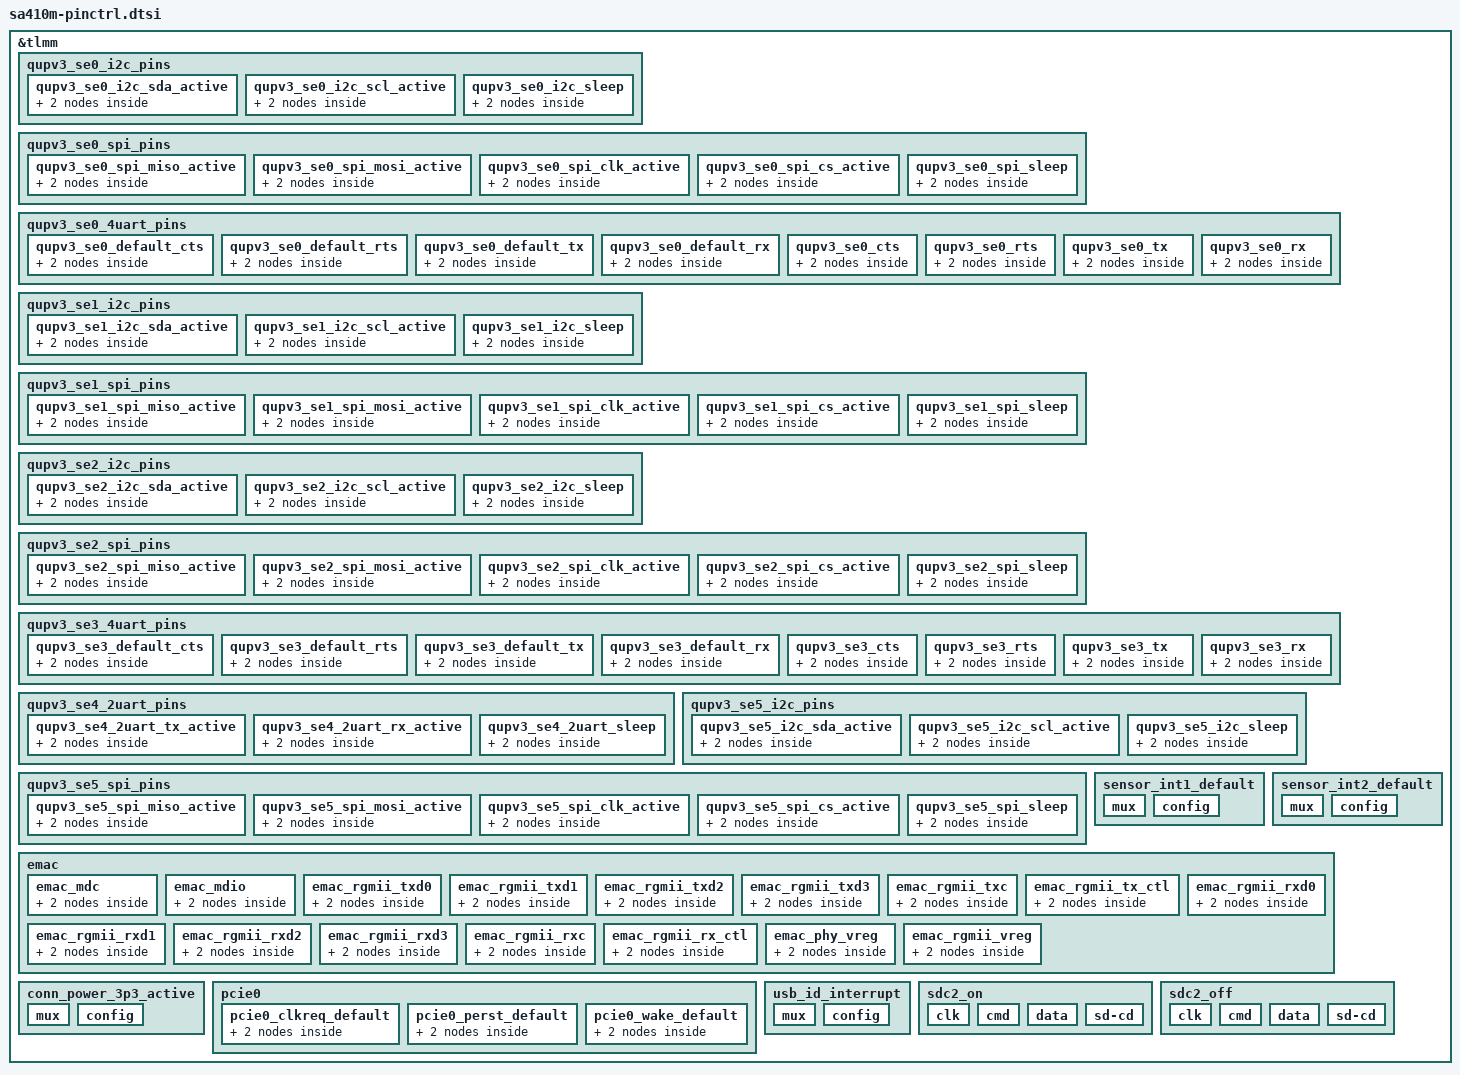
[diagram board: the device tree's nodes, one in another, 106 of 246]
&tlmm {
	qupv3_se0_i2c_pins: qupv3_se0_i2c_pins {
		qupv3_se0_i2c_sda_active: qupv3_se0_i2c_sda_active {
			mux {
				pins = "gpio0";
				function = "qup0_se0_l0";
			};

			config {
				pins = "gpio0";
				drive-strength = <2>;
				bias-pull-up;
			};
		};

		qupv3_se0_i2c_scl_active: qupv3_se0_i2c_scl_active {
			mux {
				pins = "gpio1";
				function = "qup0_se0_l1";
			};

			config {
				pins = "gpio1";
				drive-strength = <2>;
				bias-pull-up;
			};
		};

		qupv3_se0_i2c_sleep: qupv3_se0_i2c_sleep {
			mux {
				pins = "gpio0", "gpio1";
				function = "gpio";
			};

			config {
				pins = "gpio0", "gpio1";
				drive-strength = <2>;
				bias-disable;
			};
		};
	};

	qupv3_se0_spi_pins: qupv3_se0_spi_pins {
		qupv3_se0_spi_miso_active: qupv3_se0_spi_miso_active {
			mux {
				pins = "gpio0";
				function = "qup0_se0_l0";
			};

			config {
				pins = "gpio0";
				drive-strength = <6>;
				bias-disable;
			};
		};

		qupv3_se0_spi_mosi_active: qupv3_se0_spi_mosi_active {
			mux {
				pins = "gpio1";
				function = "qup0_se0_l1";
			};

			config {
				pins = "gpio1";
				drive-strength = <6>;
				bias-disable;
			};
		};

		qupv3_se0_spi_clk_active: qupv3_se0_spi_clk_active {
			mux {
				pins = "gpio2";
				function = "qup0_se0_l2";
			};

			config {
				pins = "gpio2";
				drive-strength = <6>;
				bias-disable;
			};
		};

		qupv3_se0_spi_cs_active: qupv3_se0_spi_cs_active {
			mux {
				pins = "gpio3";
				function = "qup0_se0_l3";
			};

			config {
				pins = "gpio3";
				drive-strength = <6>;
				bias-disable;
			};
		};

		qupv3_se0_spi_sleep: qupv3_se0_spi_sleep {
			mux {
				pins = "gpio0", "gpio1",
					"gpio2", "gpio3";
				function = "gpio";
			};

			config {
				pins = "gpio0", "gpio1",
					"gpio2", "gpio3";
				drive-strength = <2>;
				bias-disable;
			};
		};
	};

	qupv3_se0_4uart_pins: qupv3_se0_4uart_pins {
		qupv3_se0_default_cts: qupv3_se0_default_cts {
			mux {
				pins = "gpio0";
				function = "gpio";
			};

			config {
				pins = "gpio0";
				drive-strength = <2>;
				bias-disable;
			};
		};

		qupv3_se0_default_rts: qupv3_se0_default_rts {
			mux {
				pins = "gpio1";
				function = "gpio";
			};

			config {
				pins = "gpio1";
				drive-strength = <2>;
				bias-pull-down;
			};
		};

		qupv3_se0_default_tx: qupv3_se0_default_tx {
			mux {
				pins = "gpio2";
				function = "gpio";
			};

			config {
				pins = "gpio2";
				drive-strength = <2>;
				bias-pull-up;
			};
		};

		qupv3_se0_default_rx: qupv3_se0_default_rx {
			mux {
				pins = "gpio3";
				function = "gpio";
			};

			config {
				pins = "gpio3";
				drive-strength = <2>;
				bias-pull-down;
			};
		};

		qupv3_se0_cts: qupv3_se0_cts {
			mux {
				pins = "gpio0";
				function = "qup0_se0_l0";
			};

			config {
				pins = "gpio0";
				drive-strength = <2>;
				bias-disable;
			};
		};

		qupv3_se0_rts: qupv3_se0_rts {
			mux {
				pins = "gpio1";
				function = "qup0_se0_l1";
			};

			config {
				pins = "gpio1";
				drive-strength = <2>;
				bias-pull-down;
			};
		};

		qupv3_se0_tx: qupv3_se0_tx {
			mux {
				pins = "gpio2";
				function = "qup0_se0_l2";
			};

			config {
				pins = "gpio2";
				drive-strength = <2>;
				bias-pull-up;
			};
		};

		qupv3_se0_rx: qupv3_se0_rx {
			mux {
				pins = "gpio3";
				function = "qup0_se0_l3";
			};

			config {
				pins = "gpio3";
				drive-strength = <2>;
				bias-disable;
			};
		};
	};

	qupv3_se1_i2c_pins: qupv3_se1_i2c_pins {
		qupv3_se1_i2c_sda_active: qupv3_se1_i2c_sda_active {
			mux {
				pins = "gpio4";
				function = "qup0_se1_l0";
			};

			config {
				pins = "gpio4";
				drive-strength = <2>;
				bias-pull-up;
			};
		};

		qupv3_se1_i2c_scl_active: qupv3_se1_i2c_scl_active {
			mux {
				pins = "gpio5";
				function = "qup0_se1_l1";
			};

			config {
				pins = "gpio5";
				drive-strength = <2>;
				bias-pull-up;
			};
		};

		qupv3_se1_i2c_sleep: qupv3_se1_i2c_sleep {
			mux {
				pins = "gpio4", "gpio5";
				function = "gpio";
			};

			config {
				pins = "gpio4", "gpio5";
				drive-strength = <2>;
				bias-disable;
			};
		};
	};

	qupv3_se1_spi_pins: qupv3_se1_spi_pins {
		qupv3_se1_spi_miso_active: qupv3_se1_spi_miso_active {
			mux {
				pins = "gpio4";
				function = "qup0_se1_l0";
			};

			config {
				pins = "gpio4";
				drive-strength = <6>;
				bias-disable;
			};
		};

		qupv3_se1_spi_mosi_active: qupv3_se1_spi_mosi_active {
			mux {
				pins = "gpio5";
				function = "qup0_se1_l1";
			};

			config {
				pins = "gpio5";
				drive-strength = <6>;
				bias-disable;
			};
		};

		qupv3_se1_spi_clk_active: qupv3_se1_spi_clk_active {
			mux {
				pins = "gpio69";
				function = "qup0_se1_l2";
			};

			config {
				pins = "gpio69";
				drive-strength = <6>;
				bias-disable;
			};
		};

		qupv3_se1_spi_cs_active: qupv3_se1_spi_cs_active {
			mux {
				pins = "gpio70";
				function = "qup0_se1_l3";
			};

			config {
				pins = "gpio70";
				drive-strength = <6>;
				bias-disable;
			};
		};

		qupv3_se1_spi_sleep: qupv3_se1_spi_sleep {
			mux {
				pins = "gpio4", "gpio5",
					"gpio69", "gpio70";
				function = "gpio";
			};

			config {
				pins = "gpio4", "gpio5",
					"gpio69", "gpio70";
				drive-strength = <2>;
				bias-disable;
			};
		};
	};

	qupv3_se2_i2c_pins: qupv3_se2_i2c_pins {
		qupv3_se2_i2c_sda_active: qupv3_se2_i2c_sda_active {
			mux {
				pins = "gpio6";
				function = "qup0_se2_l0";
			};

			config {
				pins = "gpio6";
				drive-strength = <2>;
				bias-pull-up;
			};
		};

		qupv3_se2_i2c_scl_active: qupv3_se2_i2c_scl_active {
			mux {
				pins = "gpio7";
				function = "qup0_se2_l1";
			};

			config {
				pins = "gpio7";
				drive-strength = <2>;
				bias-pull-up;
			};
		};

		qupv3_se2_i2c_sleep: qupv3_se2_i2c_sleep {
			mux {
				pins = "gpio6", "gpio7";
				function = "gpio";
			};

			config {
				pins = "gpio6", "gpio7";
				drive-strength = <2>;
				bias-disable;
			};
		};
	};

	qupv3_se2_spi_pins: qupv3_se2_spi_pins {
		qupv3_se2_spi_miso_active: qupv3_se2_spi_miso_active {
			mux {
				pins = "gpio6";
				function = "qup0_se2_l0";
			};

			config {
				pins = "gpio6";
				drive-strength = <6>;
				bias-disable;
			};
		};

		qupv3_se2_spi_mosi_active: qupv3_se2_spi_mosi_active {
			mux {
				pins = "gpio7";
				function = "qup0_se2_l1";
			};

			config {
				pins = "gpio7";
				drive-strength = <6>;
				bias-disable;
			};
		};

		qupv3_se2_spi_clk_active: qupv3_se2_spi_clk_active {
			mux {
				pins = "gpio71";
				function = "qup0_se2_l2";
			};

			config {
				pins = "gpio71";
				drive-strength = <6>;
				bias-disable;
			};
		};

		qupv3_se2_spi_cs_active: qupv3_se2_spi_cs_active {
			mux {
				pins = "gpio80";
				function = "qup0_se2_l3";
			};

			config {
				pins = "gpio80";
				drive-strength = <6>;
				bias-disable;
			};
		};

		qupv3_se2_spi_sleep: qupv3_se2_spi_sleep {
			mux {
				pins = "gpio6", "gpio7",
					"gpio71", "gpio80";
				function = "gpio";
			};

			config {
				pins = "gpio6", "gpio7",
					"gpio71", "gpio80";
				drive-strength = <2>;
				bias-disable;
			};
		};
	};

	qupv3_se3_4uart_pins: qupv3_se3_4uart_pins {
		qupv3_se3_default_cts: qupv3_se3_default_cts {
			mux {
				pins = "gpio8";
				function = "gpio";
			};

			config {
				pins = "gpio8";
				drive-strength = <2>;
				bias-disable;
			};
		};

		qupv3_se3_default_rts: qupv3_se3_default_rts {
			mux {
				pins = "gpio9";
				function = "gpio";
			};

			config {
				pins = "gpio9";
				drive-strength = <2>;
				bias-pull-down;
			};
		};

		qupv3_se3_default_tx: qupv3_se3_default_tx {
			mux {
				pins = "gpio10";
				function = "gpio";
			};

			config {
				pins = "gpio10";
				drive-strength = <2>;
				bias-pull-up;
			};
		};

		qupv3_se3_default_rx: qupv3_se3_default_rx {
			mux {
				pins = "gpio11";
				function = "gpio";
			};

			config {
				pins = "gpio11";
				drive-strength = <2>;
				bias-pull-down;
			};
		};

		qupv3_se3_cts: qupv3_se3_cts {
			mux {
				pins = "gpio8";
				function = "qup0_se3_l0";
			};

			config {
				pins = "gpio8";
				drive-strength = <2>;
				bias-disable;
			};
		};

		qupv3_se3_rts: qupv3_se3_rts {
			mux {
				pins = "gpio9";
				function = "qup0_se3_l1";
			};

			config {
				pins = "gpio9";
				drive-strength = <2>;
				bias-pull-down;
			};
		};

		qupv3_se3_tx: qupv3_se3_tx {
			mux {
				pins = "gpio10";
				function = "qup0_se3_l2";
			};

			config {
				pins = "gpio10";
				drive-strength = <2>;
				bias-pull-up;
			};
		};

		qupv3_se3_rx: qupv3_se3_rx {
			mux {
				pins = "gpio11";
				function = "qup0_se3_l3";
			};

			config {
				pins = "gpio11";
				drive-strength = <2>;
				bias-disable;
			};
		};
	};

	qupv3_se4_2uart_pins: qupv3_se4_2uart_pins {
		qupv3_se4_2uart_tx_active: qupv3_se4_2uart_tx_active {
			mux {
				pins = "gpio12";
				function = "qup0_se4_l2";
			};

			config {
				pins = "gpio12";
				drive-strength = <2>;
				bias-disable;
			};
		};

		qupv3_se4_2uart_rx_active: qupv3_se4_2uart_rx_active {
			mux {
				pins = "gpio13";
				function = "qup0_se4_l3";
			};

			config {
				pins = "gpio13";
				drive-strength = <2>;
				bias-disable;
			};
		};

		qupv3_se4_2uart_sleep: qupv3_se4_2uart_sleep {
			mux {
				pins = "gpio12", "gpio13";
				function = "gpio";
			};

			config {
				pins = "gpio12", "gpio13";
				drive-strength = <2>;
				bias-disable;
			};
		};
	};

	qupv3_se5_i2c_pins: qupv3_se5_i2c_pins {
		qupv3_se5_i2c_sda_active: qupv3_se5_i2c_sda_active {
			mux {
				pins = "gpio14";
				function = "qup0_se5_l0";
			};

			config {
				pins = "gpio14";
				drive-strength = <2>;
				bias-pull-up;
			};
		};

		qupv3_se5_i2c_scl_active: qupv3_se5_i2c_scl_active {
			mux {
				pins = "gpio15";
				function = "qup0_se5_l1";
			};

			config {
				pins = "gpio15";
				drive-strength = <2>;
				bias-pull-up;
			};
		};

		qupv3_se5_i2c_sleep: qupv3_se5_i2c_sleep {
			mux {
				pins = "gpio14", "gpio15";
				function = "gpio";
			};

			config {
				pins = "gpio14", "gpio15";
				drive-strength = <2>;
				bias-disable;
			};
		};
	};

	qupv3_se5_spi_pins: qupv3_se5_spi_pins {
		qupv3_se5_spi_miso_active: qupv3_se5_spi_miso_active {
			mux {
				pins = "gpio14";
				function = "qup0_se5_l0";
			};

			config {
				pins = "gpio14";
				drive-strength = <6>;
				bias-disable;
			};
		};

		qupv3_se5_spi_mosi_active: qupv3_se5_spi_mosi_active {
			mux {
				pins = "gpio15";
				function = "qup0_se5_l1";
			};

			config {
				pins = "gpio15";
				drive-strength = <6>;
				bias-disable;
			};
		};

		qupv3_se5_spi_clk_active: qupv3_se5_spi_clk_active {
			mux {
				pins = "gpio16";
				function = "qup0_se5_l2";
			};

			config {
				pins = "gpio16";
				drive-strength = <6>;
				bias-disable;
			};
		};

		qupv3_se5_spi_cs_active: qupv3_se5_spi_cs_active {
			mux {
				pins = "gpio17";
				function = "qup0_se5_l3";
			};

			config {
				pins = "gpio17";
				drive-strength = <6>;
				bias-disable;
			};
		};

		qupv3_se5_spi_sleep: qupv3_se5_spi_sleep {
			mux {
				pins = "gpio14", "gpio15",
					"gpio16", "gpio17";
				function = "gpio";
			};

			config {
				pins = "gpio14", "gpio15",
					"gpio16", "gpio17";
				drive-strength = <2>;
				bias-disable;
			};
		};
	};

	sensor_int1_default: sensor_int1_default {
			mux {
				pins = "gpio31";
				function = "gpio";
			};

			config {
				pins = "gpio31";
				drive-strength = <16>; /* 16 mA */
				bias-pull-down; /* pull down */
			};
	};

	sensor_int2_default: sensor_int2_default {
			mux {
				pins = "gpio32";
				function = "gpio";
			};

			config {
				pins = "gpio32";
				drive-strength = <16>; /* 16 mA */
				bias-pull-down; /* pull down */
			};
	};

	emac {

		emac_mdc: emac_mdc {
			mux {
				pins = "gpio136";
				function = "RGMII0_MDC";
			};

			config {
				pins = "gpio136";
				bias-pull-down;
				enable-input = <0>;
				drive-strength = <16>;
			};
		};

		emac_mdio: emac_mdio {
			mux {
				pins = "gpio135";
				function = "RGMII0_MDIO";
			};

			config {
				pins = "gpio135";
				bias-pull-down;
				drive-strength = <16>;
			};
		};

		emac_rgmii_txd0: emac_rgmii_txd0 {
			mux {
				pins = "gpio131";
				function = "RGMII0_TXD0";
			};

			config {
				pins = "gpio131";
				bias-pull-up;
				drive-strength = <16>;
			};
		};

		emac_rgmii_txd1: emac_rgmii_txd1 {
			mux {
				pins = "gpio132";
				function = "RGMII0_TXD1";
			};

			config {
				pins = "gpio132";
				bias-pull-up;
				drive-strength = <16>;
			};
		};

		emac_rgmii_txd2: emac_rgmii_txd2 {
			mux {
				pins = "gpio133";
				function = "RGMII0_TXD2";
			};

			config {
				pins = "gpio133";
				bias-pull-up;
				drive-strength = <16>;
			};
		};

		emac_rgmii_txd3: emac_rgmii_txd3 {
			mux {
				pins = "gpio134";
				function = "RGMII0_TXD3";
			};

			config {
				pins = "gpio134";
				bias-pull-up;
				drive-strength = <16>;
			};
		};

		emac_rgmii_txc: emac_rgmii_txc {
			mux {
				pins = "gpio91";
				function = "RGMII0_TXC";
			};

			config {
				pins = "gpio91";
				bias-pull-up;
				drive-strength = <16>;
			};
		};

		emac_rgmii_tx_ctl: emac_rgmii_tx_ctl {
			mux {
				pins = "gpio90";
				function = "RGMII0_TX_CTL";
			};

			config {
				pins = "gpio90";
				bias-pull-up;
				drive-strength = <16>;
			};
		};

		emac_rgmii_rxd0: emac_rgmii_rxd0 {
			mux {
				pins = "gpio21";
				function = "RGMII0_RXD0";
			};

			config {
				pins = "gpio21";
				bias-disable;  /* NO pull */
				drive-strength = <16>;  /* 16MA */
			};
		};

		emac_rgmii_rxd1: emac_rgmii_rxd1 {
			mux {
				pins = "gpio27";
				function = "RGMII0_RXD1";
			};

			config {
				pins = "gpio27";
				bias-disable;  /* NO pull */
				drive-strength = <16>;
			};
		};

		emac_rgmii_rxd2: emac_rgmii_rxd2 {
			mux {
				pins = "gpio28";
				function = "RGMII0_RXD2";
			};

			config {
				pins = "gpio28";
				bias-disable;	/* NO pull */
				drive-strength = <16>;
			};
		};

		emac_rgmii_rxd3: emac_rgmii_rxd3 {
			mux {
				pins = "gpio87";
				function = "RGMII0_RXD3";
			};

			config {
				pins = "gpio87";
				bias-disable;	/* NO pull */
				drive-strength = <16>;
			};
		};

		emac_rgmii_rxc: emac_rgmii_rxc {
			mux {
				pins = "gpio20";
				function = "RGMII0_RXC";
			};

			config {
				pins = "gpio20";
				bias-disable;	/* NO pull */
				drive-strength = <16>;
			};
		};

		emac_rgmii_rx_ctl: emac_rgmii_rx_ctl {
			mux {
				pins = "gpio18";
				function = "RGMII0_RX_CTL";
			};

			config {
				pins = "gpio18";
				bias-disable;  /* NO pull */
				drive-strength = <16>;
			};
		};

		emac_phy_vreg: emac_phy_vreg {
			mux {
				pins = "gpio115";
				function = "gpio";
			};

			config {
				pins = "gpio115";
				bias-disable;   /* NO pull */
				drive-strength = <16>;
			};
		};

		emac_rgmii_vreg: emac_rgmii_vreg {
			mux {
				pins = "gpio116";
				function = "gpio";
			};

			config {
				pins = "gpio116";
				bias-disable;  /* NO pull */
				drive-strength = <16>;
			};
		};

	};

	conn_power_3p3_active: conn_power_3p3_active {
			mux {
				pins = "gpio23";
				function = "gpio";
			};

			config {
				pins = "gpio23";
				drive-strength = <2>; /* 2 mA */
				bias-pull-down; /* pull down */
			};
	};

	pcie0 {
		pcie0_clkreq_default: pcie0_clkreq_default {
			mux {
					pins = "gpio24";
					function = "PCIE0_CLK_REQ";
			};

			config	{
					pins = "gpio24";
					drive-strength = <2>;
					bias-pull-up;
			};
		};

		pcie0_perst_default: pcie0_perst_default {
			mux {
					pins = "gpio25";
					function = "gpio";
			};

			config  {
					pins = "gpio25";
					drive-strength = <2>;
					bias-pull-down;
			};
		};

		pcie0_wake_default: pcie0_wake_default {
			mux {
					pins = "gpio26";
					function = "gpio";
			};

			config  {
					pins = "gpio26";
					drive-strength = <2>;
					bias-pull-up;
			};
		};
	};

	usb_id_interrupt: usb_id_interrupt {
		mux {
			pins = "gpio89";
			function = "gpio";
		};

		config {
			pins = "gpio89";
			bias-pull-up;
			input-enable;
		};
	};

	sdc2_on: sdc2_on {
		clk {
			pins = "sdc2_clk";
			bias-disable;
			drive-strength = <16>;
		};

		cmd {
			pins = "sdc2_cmd";
			bias-pull-up;
			drive-strength = <10>;
		};

		data {
			pins = "sdc2_data";
			bias-pull-up;
			drive-strength = <10>;
		};

		sd-cd {
			pins = "gpio88";
			bias-pull-up;
			drive-strength = <2>;
		};
	};

	sdc2_off: sdc2_off {
		clk {
			pins = "sdc2_clk";
			bias-disable;
			drive-strength = <2>;
		};

		cmd {
			pins = "sdc2_cmd";
			bias-pull-up;
			drive-strength = <2>;
		};

		data {
			pins = "sdc2_data";
			bias-pull-up;
			drive-strength = <2>;
		};

		sd-cd {
			pins = "gpio88";
			bias-pull-up;
			drive-strength = <2>;
		};
	};
};
